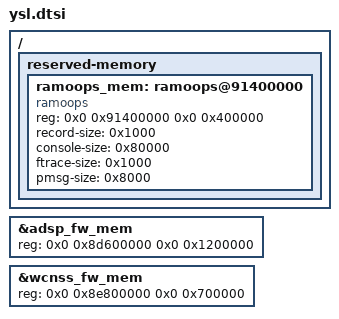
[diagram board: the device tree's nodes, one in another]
/ {
	reserved-memory {
		ramoops_mem: ramoops@91400000 {
			compatible = "ramoops";
			reg = <0x0 0x91400000  0x0 0x400000>;
			record-size = <0x1000>;
			console-size = <0x80000>;
			ftrace-size = <0x1000>;
			pmsg-size = <0x8000>;
		};
	};
};

&adsp_fw_mem {
	reg = <0x0 0x8d600000 0x0 0x1200000>;
};
&wcnss_fw_mem {
	reg = <0x0 0x8e800000 0x0 0x700000>;
};

#include "../common/sdhc.dtsi"
#include "../common/pinctrl.dtsi"
#include "pinctrl.dtsi"
#include "ysl-pinctrl.dtsi"
#include "pmic.dtsi"
#include "battery.dtsi"
#include "display.dtsi"
#include "touchscreen.dtsi"
#include "camera.dtsi"
#include "audio.dtsi"
#include "misc.dtsi"
#include "fingerprint.dtsi"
